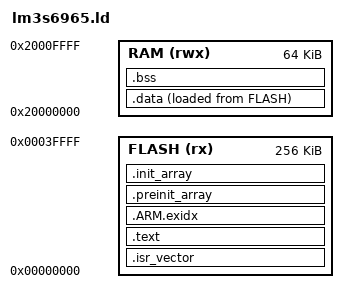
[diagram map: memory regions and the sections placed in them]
/*
 * BareMetal-RTOS - LM3S6965 linker script (256 KiB flash, 64 KiB SRAM)
 * Copyright (c) 2026 Swayam Shakya
 * SPDX-License-Identifier: MIT
 */
ENTRY(Reset_Handler)

MEMORY
{
    FLASH (rx)  : ORIGIN = 0x00000000, LENGTH = 256K
    RAM   (rwx) : ORIGIN = 0x20000000, LENGTH = 64K
}

_estack = ORIGIN(RAM) + LENGTH(RAM);
_min_main_stack = 0x800;

SECTIONS
{
    .isr_vector : ALIGN(4)
    {
        KEEP(*(.isr_vector))
    } > FLASH

    .text : ALIGN(4)
    {
        *(.text*)
        *(.rodata*)
        KEEP(*(.init))
        KEEP(*(.fini))
        . = ALIGN(4);
    } > FLASH

    .ARM.exidx : { *(.ARM.exidx* .gnu.linkonce.armexidx.*) } > FLASH

    .preinit_array : ALIGN(4)
    {
        PROVIDE_HIDDEN(__preinit_array_start = .);
        KEEP(*(.preinit_array*))
        PROVIDE_HIDDEN(__preinit_array_end = .);
    } > FLASH

    .init_array : ALIGN(4)
    {
        PROVIDE_HIDDEN(__init_array_start = .);
        KEEP(*(SORT(.init_array.*)))
        KEEP(*(.init_array*))
        PROVIDE_HIDDEN(__init_array_end = .);
    } > FLASH

    _sidata = LOADADDR(.data);

    .data : ALIGN(4)
    {
        _sdata = .;
        *(.data*)
        . = ALIGN(4);
        _edata = .;
    } > RAM AT > FLASH

    .bss (NOLOAD) : ALIGN(4)
    {
        _sbss = .;
        *(.bss*)
        *(COMMON)
        . = ALIGN(4);
        _ebss = .;
    } > RAM

    /* Fail the link if globals leave too little room for the main (exception) stack. */
    ASSERT(_ebss + _min_main_stack <= _estack, "RAM overflow: not enough room for main stack")
}
